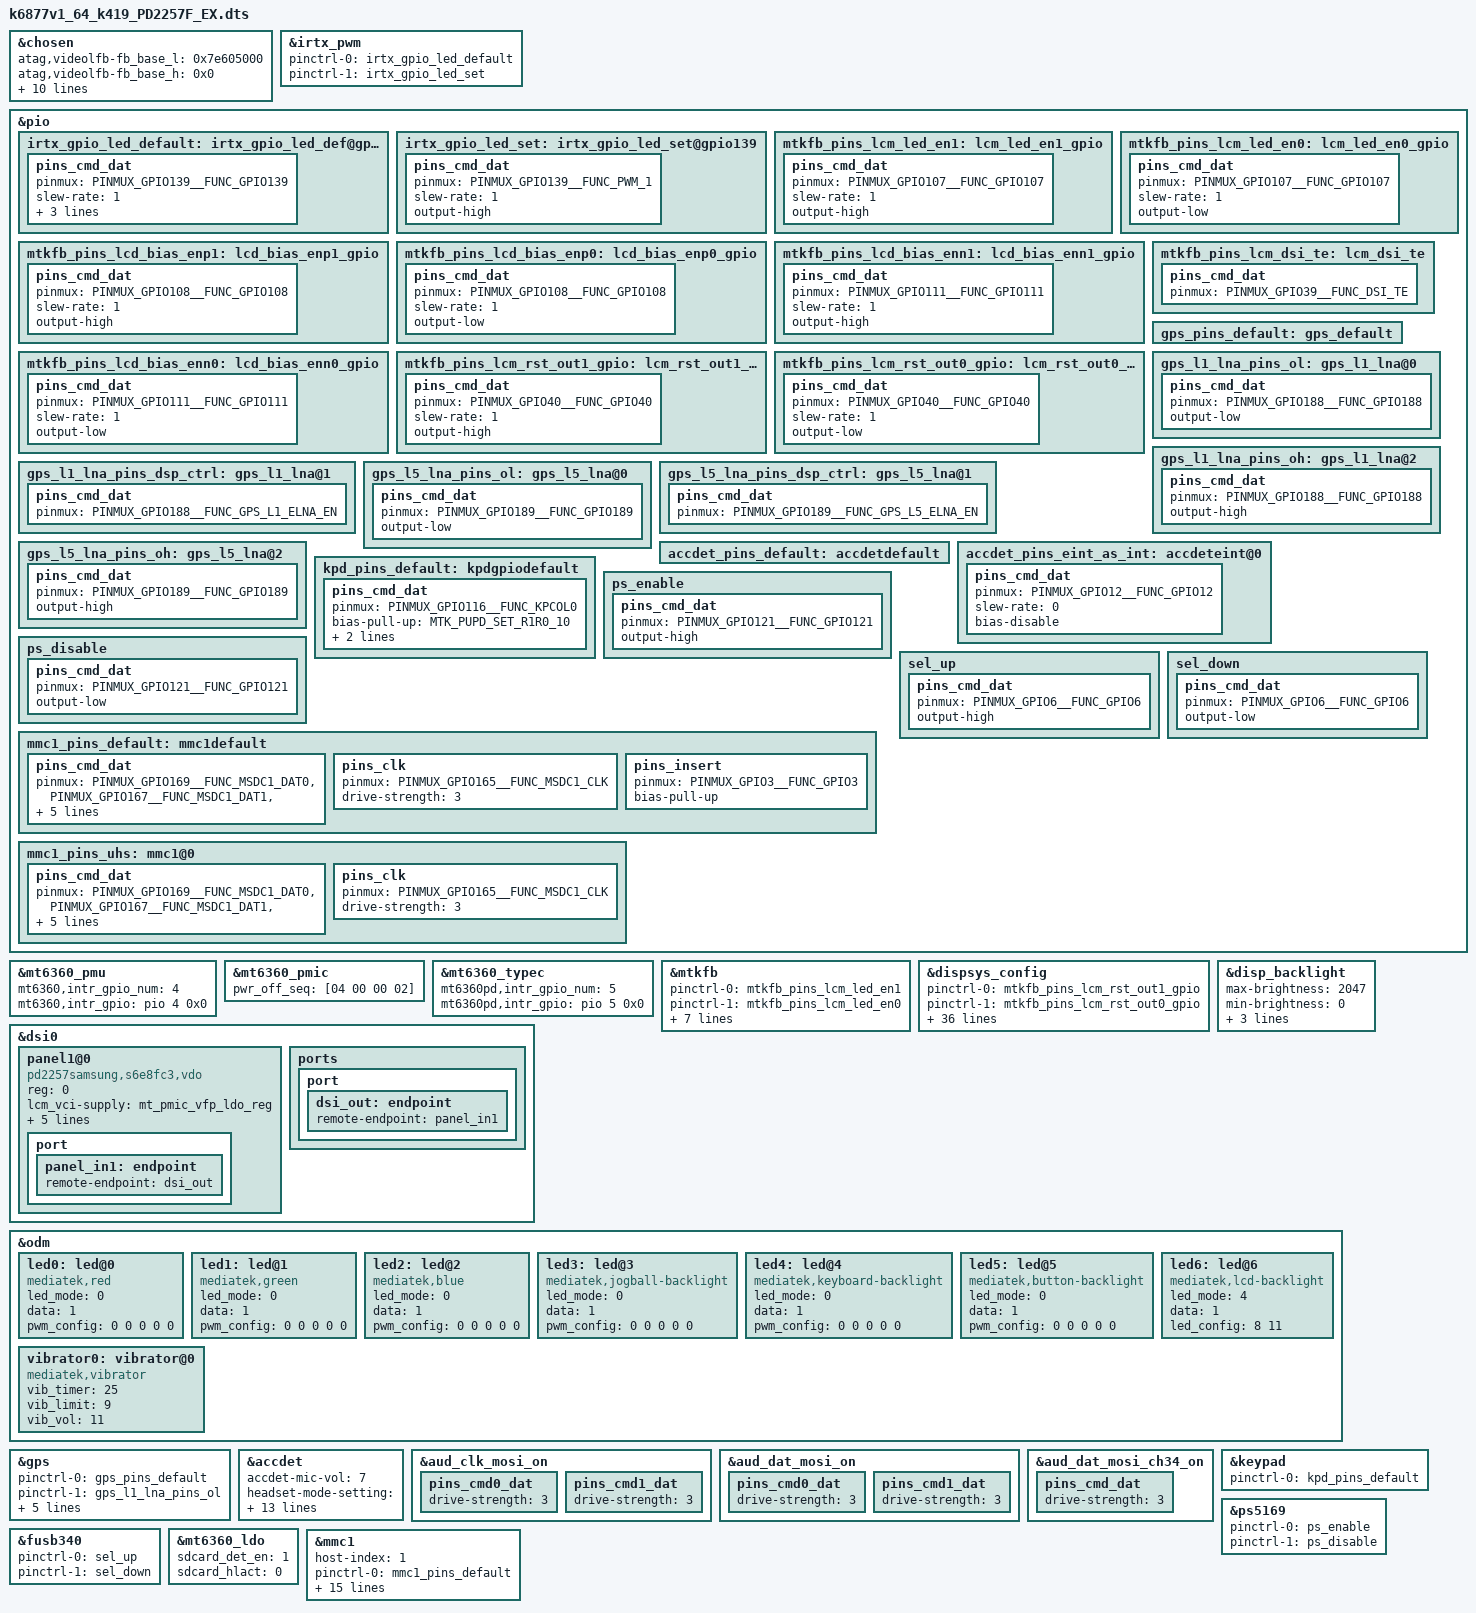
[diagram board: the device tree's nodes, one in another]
// SPDX-License-Identifier: GPL-2.0
/*
 * Copyright (c) 2021 MediaTek Inc.
 */

/dts-v1/;
/plugin/;
#include <generated/autoconf.h>
#include <dt-bindings/interrupt-controller/irq.h>
#include <dt-bindings/interrupt-controller/arm-gic.h>
#include <dt-bindings/pinctrl/mt6877-pinfunc.h>
#include "mtk6877t-vivo-tp-PD2257F_EX.dtsi"
#include "mediatek/fingerprint/mtk6877-vivo-fp-PD2257F_EX.dtsi"
#include <dt-bindings/gpio/gpio.h>
#include <dt-bindings/mmc/mt6877-msdc.h>

/* chosen */
&chosen {
	atag,videolfb-fb_base_l = <0x7e605000>;
	atag,videolfb-fb_base_h = <0x0>;
	atag,videolfb-islcmfound = <1>;
	atag,videolfb-islcm_inited = <0>;
	atag,videolfb-fps= <6000>;
	atag,videolfb-vramSize= <0x1be0000>;
	default-backlight-level = <573>;
	atag,videolfb-project-name= "pd2257";
	atag,vivo-dsi-panel-type = "oled";
	atag,hbm-event-support;
	atag,videolfb-lcmname=
		"td4330_fhdp_dsi_cmd_auo_rt4831_drv";
};

/* IRTX GPIO Start */
&irtx_pwm {
	pinctrl-names = "irtx_gpio_led_default", "irtx_gpio_led_set";
	pinctrl-0 = <&irtx_gpio_led_default>;
	pinctrl-1 = <&irtx_gpio_led_set>;
	status = "okay";
};

&pio {
       /* IRTX GPIO Settings -Start */
       /* default: GPIO0, output, high */
       irtx_gpio_led_default:irtx_gpio_led_def@gpio139 {
               pins_cmd_dat {
                       pinmux = <PINMUX_GPIO139__FUNC_GPIO139>;
                       slew-rate = <1>;
                       bias-disable;
                       output-low;
                       input-schmitt-enable = <0>;
               };
       };

       irtx_gpio_led_set:irtx_gpio_led_set@gpio139 {
               pins_cmd_dat {
                       pinmux = <PINMUX_GPIO139__FUNC_PWM_1>;
                       slew-rate = <1>;
                       output-high;
               };
       };
};

/* IRTX GPIO Settings -End */

&mt6360_pmu {
	mt6360,intr_gpio_num = <4>; /* direct defined GPIO num */
	mt6360,intr_gpio = <&pio 4 0x0>;
};

&mt6360_pmic {
	pwr_off_seq = [04 00 00 02];
};

&mt6360_typec {
	mt6360pd,intr_gpio_num = <5>; /* direct defined GPIO num */
	mt6360pd,intr_gpio = <&pio 5 0x0>;
};

&pio {
	mtkfb_pins_lcm_led_en1: lcm_led_en1_gpio {
		pins_cmd_dat {
			pinmux = <PINMUX_GPIO107__FUNC_GPIO107>;
			slew-rate = <1>;
			output-high;
		};
	};

	mtkfb_pins_lcm_led_en0: lcm_led_en0_gpio {
		pins_cmd_dat {
			pinmux = <PINMUX_GPIO107__FUNC_GPIO107>;
			slew-rate = <1>;
			output-low;
		};
	};

	mtkfb_pins_lcd_bias_enp1: lcd_bias_enp1_gpio {
		pins_cmd_dat {
			pinmux = <PINMUX_GPIO108__FUNC_GPIO108>;
			slew-rate = <1>;
			output-high;
		};
	};

	mtkfb_pins_lcd_bias_enp0: lcd_bias_enp0_gpio {
		pins_cmd_dat {
			pinmux = <PINMUX_GPIO108__FUNC_GPIO108>;
			slew-rate = <1>;
			output-low;
		};
	};

	mtkfb_pins_lcd_bias_enn1: lcd_bias_enn1_gpio {
		pins_cmd_dat {
			pinmux = <PINMUX_GPIO111__FUNC_GPIO111>;
			slew-rate = <1>;
			output-high;
		};
	};

	mtkfb_pins_lcd_bias_enn0: lcd_bias_enn0_gpio {
		pins_cmd_dat {
			pinmux = <PINMUX_GPIO111__FUNC_GPIO111>;
			slew-rate = <1>;
			output-low;
		};
	};

	mtkfb_pins_lcm_rst_out1_gpio: lcm_rst_out1_gpio {
		pins_cmd_dat {
			pinmux = <PINMUX_GPIO40__FUNC_GPIO40>;
			slew-rate = <1>;
			output-high;
		};
	};

	mtkfb_pins_lcm_rst_out0_gpio: lcm_rst_out0_gpio {
		pins_cmd_dat {
			pinmux = <PINMUX_GPIO40__FUNC_GPIO40>;
			slew-rate = <1>;
			output-low;
		};
	};
	mtkfb_pins_lcm_dsi_te: lcm_dsi_te {
		pins_cmd_dat {
			pinmux = <PINMUX_GPIO39__FUNC_DSI_TE>;
		};
	};
};

&mtkfb {
	pinctrl-names = "lcm_led_en1_gpio", "lcm_led_en0_gpio",
		"lcd_bias_enp1_gpio", "lcd_bias_enp0_gpio",
		"lcd_bias_enn1_gpio", "lcd_bias_enn0_gpio",
		"lcm_rst_out1_gpio", "lcm_rst_out0_gpio",
		"mode_te_te";
	pinctrl-0 = <&mtkfb_pins_lcm_led_en1>;
	pinctrl-1 = <&mtkfb_pins_lcm_led_en0>;
	pinctrl-2 = <&mtkfb_pins_lcd_bias_enp1>;
	pinctrl-3 = <&mtkfb_pins_lcd_bias_enp0>;
	pinctrl-4 = <&mtkfb_pins_lcd_bias_enn1>;
	pinctrl-5 = <&mtkfb_pins_lcd_bias_enn0>;
	pinctrl-6 = <&mtkfb_pins_lcm_rst_out1_gpio>;
	pinctrl-7 = <&mtkfb_pins_lcm_rst_out0_gpio>;
	pinctrl-8 = <&mtkfb_pins_lcm_dsi_te>;
	status = "okay";
};
&dispsys_config {
	pinctrl-names =
		"lcm_rst_out1_gpio", "lcm_rst_out0_gpio",
		"mode_te_te";
	pinctrl-0 = <&mtkfb_pins_lcm_rst_out1_gpio>;
	pinctrl-1 = <&mtkfb_pins_lcm_rst_out0_gpio>;
	pinctrl-2 = <&mtkfb_pins_lcm_dsi_te>;
	status = "okay";
	helper-name = "MTK_DRM_OPT_STAGE",
	"MTK_DRM_OPT_USE_CMDQ",
	"MTK_DRM_OPT_USE_M4U",
	"MTK_DRM_OPT_SODI_SUPPORT",
	"MTK_DRM_OPT_IDLE_MGR",
	"MTK_DRM_OPT_IDLEMGR_SWTCH_DECOUPLE",
	"MTK_DRM_OPT_IDLEMGR_BY_REPAINT",
	"MTK_DRM_OPT_IDLEMGR_ENTER_ULPS",
	"MTK_DRM_OPT_IDLEMGR_KEEP_LP11",
	"MTK_DRM_OPT_DYNAMIC_RDMA_GOLDEN_SETTING",
	"MTK_DRM_OPT_IDLEMGR_DISABLE_ROUTINE_IRQ",
	"MTK_DRM_OPT_MET_LOG",
	"MTK_DRM_OPT_USE_PQ",
	"MTK_DRM_OPT_ESD_CHECK_RECOVERY",
	"MTK_DRM_OPT_ESD_CHECK_SWITCH",
	"MTK_DRM_OPT_PRESENT_FENCE",
	"MTK_DRM_OPT_RDMA_UNDERFLOW_AEE",
	"MTK_DRM_OPT_DSI_UNDERRUN_AEE",
	"MTK_DRM_OPT_HRT",
	"MTK_DRM_OPT_HRT_MODE",
	"MTK_DRM_OPT_DELAYED_TRIGGER",
	"MTK_DRM_OPT_OVL_EXT_LAYER",
	"MTK_DRM_OPT_AOD",
	"MTK_DRM_OPT_RPO",
	"MTK_DRM_OPT_DUAL_PIPE",
	"MTK_DRM_OPT_DC_BY_HRT",
	"MTK_DRM_OPT_OVL_WCG",
	"MTK_DRM_OPT_OVL_SBCH",
	"MTK_DRM_OPT_COMMIT_NO_WAIT_VBLANK",
	"MTK_DRM_OPT_MET",
	"MTK_DRM_OPT_REG_PARSER_RAW_DUMP",
	"MTK_DRM_OPT_VP_PQ",
	"MTK_DRM_OPT_GAME_PQ",
	"MTK_DRM_OPT_MMPATH",
	"MTK_DRM_OPT_HBM",
	"MTK_DRM_OPT_VDS_PATH_SWITCH",
	"MTK_DRM_OPT_LAYER_REC",
	"MTK_DRM_OPT_CLEAR_LAYER",
	"MTK_DRM_OPT_LFR",
	"MTK_DRM_OPT_DYN_MIPI_CHANGE",
	"MTK_DRM_OPT_SF_PF";

	helper-value = <0>, /*MTK_DRM_OPT_STAGE*/
		<1>, /*MTK_DRM_OPT_USE_CMDQ*/
		<1>, /*MTK_DRM_OPT_USE_M4U*/
		<0>, /*MTK_DRM_OPT_SODI_SUPPORT*/
		<1>, /*MTK_DRM_OPT_IDLE_MGR*/
		<0>, /*MTK_DRM_OPT_IDLEMGR_SWTCH_DECOUPLE*/
		<1>, /*MTK_DRM_OPT_IDLEMGR_BY_REPAINT*/
		<0>, /*MTK_DRM_OPT_IDLEMGR_ENTER_ULPS*/
		<0>, /*MTK_DRM_OPT_IDLEMGR_KEEP_LP11*/
		<0>, /*MTK_DRM_OPT_DYNAMIC_RDMA_GOLDEN_SETTING*/
		<1>, /*MTK_DRM_OPT_IDLEMGR_DISABLE_ROUTINE_IRQ*/
		<0>, /*MTK_DRM_OPT_MET_LOG*/
		<1>, /*MTK_DRM_OPT_USE_PQ*/
		<1>, /*MTK_DRM_OPT_ESD_CHECK_RECOVERY*/
		<1>, /*MTK_DRM_OPT_ESD_CHECK_SWITCH*/
		<1>, /*MTK_DRM_OPT_PRESENT_FENCE*/
		<1>, /*MTK_DRM_OPT_RDMA_UNDERFLOW_AEE*/
		<1>, /*MTK_DRM_OPT_DSI_UNDERRUN_AEE*/
		<1>, /*MTK_DRM_OPT_HRT*/
		<1>, /*MTK_DRM_OPT_HRT_MODE*/
		<0>, /*MTK_DRM_OPT_DELAYED_TRIGGER*/
		<1>, /*MTK_DRM_OPT_OVL_EXT_LAYER*/
		<1>, /*MTK_DRM_OPT_AOD*/
		<1>, /*MTK_DRM_OPT_RPO*/
		<0>, /*MTK_DRM_OPT_DUAL_PIPE*/
		<0>, /*MTK_DRM_OPT_DC_BY_HRT*/
		<0>, /*MTK_DRM_OPT_OVL_WCG*/
		<0>, /*MTK_DRM_OPT_OVL_SBCH*/
		<1>, /*MTK_DRM_OPT_COMMIT_NO_WAIT_VBLANK*/
		<0>, /*MTK_DRM_OPT_MET*/
		<0>, /*MTK_DRM_OPT_REG_PARSER_RAW_DUMP*/
		<0>, /*MTK_DRM_OPT_VP_PQ*/
		<0>, /*MTK_DRM_OPT_GAME_PQ*/
		<0>, /*MTK_DRM_OPT_MMPATH*/
		<1>, /*MTK_DRM_OPT_HBM*/
		<0>, /*MTK_DRM_OPT_VDS_PATH_SWITCH*/
		<0>, /*MTK_DRM_OPT_LAYER_REC*/
		<1>, /*MTK_DRM_OPT_CLEAR_LAYER*/
		<0>, /*MTK_DRM_OPT_LFR*/
		<1>, /*MTK_DRM_OPT_DYN_MIPI_CHANGE*/
		<0>; /*MTK_DRM_OPT_SF_PF*/
};
&disp_backlight {
	max-brightness = <2047>;
	min-brightness = <0>;
	led-bits = <11>;
	default-brightness = <573>;
	default-state = "on";
};

&dsi0 {
	status = "okay";
	#address-cells = <1>;
	#size-cells = <0>;
	panel1@0 {
		compatible = "pd2257samsung,s6e8fc3,vdo";
		reg = <0>;
		lcm_vci-supply = <&mt_pmic_vfp_ldo_reg>; //LDO1
		vddi_en-gpios = <&pio 16 0>;
		vddr_en-gpios = <&pio 139 0>;
		err_flag-gpios = <&pio 9 0>;
		elvdd_ctrl-gpios = <&pio 138 0>;
		reset-gpios = <&pio 40 0>;
		pinctrl-names = "default";
		port {
			panel_in1: endpoint {
				remote-endpoint = <&dsi_out>;
			};
		};
	};
	ports {
		port {
			dsi_out: endpoint {
				remote-endpoint = <&panel_in1>;
			};
		};
	};
};

&odm {
	led0:led@0 {
		compatible = "mediatek,red";
		led_mode = <0>;
		data = <1>;
		pwm_config = <0 0 0 0 0>;
	};
	led1:led@1 {
		compatible = "mediatek,green";
		led_mode = <0>;
		data = <1>;
		pwm_config = <0 0 0 0 0>;
	};
	led2:led@2 {
		compatible = "mediatek,blue";
		led_mode = <0>;
		data = <1>;
		pwm_config = <0 0 0 0 0>;
	};
	led3:led@3 {
		compatible = "mediatek,jogball-backlight";
		led_mode = <0>;
		data = <1>;
		pwm_config = <0 0 0 0 0>;
	};
	led4:led@4 {
		compatible = "mediatek,keyboard-backlight";
		led_mode = <0>;
		data = <1>;
		pwm_config = <0 0 0 0 0>;
	};
	led5:led@5 {
		compatible = "mediatek,button-backlight";
		led_mode = <0>;
		data = <1>;
		pwm_config = <0 0 0 0 0>;
	};
	led6:led@6 {
		compatible = "mediatek,lcd-backlight";
		led_mode = <4>; /*5:cpu pwm 4:lcm pwm*/
		data = <1>;
		led_config = <8 11>;
	};
	vibrator0:vibrator@0 {
		compatible = "mediatek,vibrator";
		vib_timer = <25>;
		vib_limit = <9>;
		vib_vol= <11>;
	};
};

/* GPS GPIO standardization start */
&pio {
	gps_pins_default: gps_default {
	};
	gps_l1_lna_pins_ol: gps_l1_lna@0 {
		pins_cmd_dat {
			pinmux = <PINMUX_GPIO188__FUNC_GPIO188>;
			output-low;
		};
	};
	gps_l1_lna_pins_dsp_ctrl: gps_l1_lna@1 {
		pins_cmd_dat {
			pinmux = <PINMUX_GPIO188__FUNC_GPS_L1_ELNA_EN>;
		};
	};
	gps_l1_lna_pins_oh: gps_l1_lna@2 {
		pins_cmd_dat {
			pinmux = <PINMUX_GPIO188__FUNC_GPIO188>;
			output-high;
		};
	};
	gps_l5_lna_pins_ol: gps_l5_lna@0 {
		pins_cmd_dat {
			pinmux = <PINMUX_GPIO189__FUNC_GPIO189>;
			output-low;
		};
	};
	gps_l5_lna_pins_dsp_ctrl: gps_l5_lna@1 {
		pins_cmd_dat {
			pinmux = <PINMUX_GPIO189__FUNC_GPS_L5_ELNA_EN>;
		};
	};
	gps_l5_lna_pins_oh: gps_l5_lna@2 {
		pins_cmd_dat {
			pinmux = <PINMUX_GPIO189__FUNC_GPIO189>;
			output-high;
		};
	};
};
&gps {
	pinctrl-names = "default",
		"gps_l1_lna_disable",
		"gps_l1_lna_dsp_ctrl",
		"gps_l1_lna_enable",
		"gps_l5_lna_disable",
		"gps_l5_lna_dsp_ctrl",
		"gps_l5_lna_enable";
	pinctrl-0 = <&gps_pins_default>;
	pinctrl-1 = <&gps_l1_lna_pins_ol>;
	pinctrl-2 = <&gps_l1_lna_pins_dsp_ctrl>;
	pinctrl-3 = <&gps_l1_lna_pins_oh>;
	pinctrl-4 = <&gps_l5_lna_pins_ol>;
	pinctrl-5 = <&gps_l5_lna_pins_dsp_ctrl>;
	pinctrl-6 = <&gps_l5_lna_pins_oh>;
	status = "okay";
};
/* GPS GPIO standardization end */

&accdet {
	/* accdet micbias voltage: 0x09:2.85v 0x08:2.8v 0x07,
	 * 2.7v;0x05,2.5v;0x02,1.9v
	 */
	accdet-mic-vol = <7>;
	/* accdet pwm_width, pwm_thresh, fall_delay, rise_delay
	 * debounce0, debounce1, debounce3, debounce4
	 * eint pwm_width, eint pwm_thresh
	 * eint deb(debounce0, debounce1, debounce2, debounce3), inv_debounce
	 */
	headset-mode-setting = <0x500 0x500 1 0x1f0
				0x800 0x800 0x2000 0x44
				0x4 0x1
				0x5 0x3 0x3 0x5 0xe>;
	accdet-plugout-debounce = <16>;
	/*1:ACC mode, 2:low cost without in bias, 6:low cost with in bias*/
	accdet-mic-mode = <2>;
	/*0--MD_MAX--UP_MAX--DW_MAX*/
	headset-three-key-threshold = <0 90 210 430>;
	headset-three-key-threshold-CDD = <0 121 192 600>;
	/*0--MD_MAX--VOICE_MAX--UP_MAX--DW_MAX*/
	headset-four-key-threshold = <0 60 106 210 430>;

	/* select VTH to 2v and 500k, use internal resitance */
	eint_use_ext_res = <0>;
	pinctrl-names = "default", "state_eint_as_int";
	pinctrl-0 = <&accdet_pins_default>;
	pinctrl-1 = <&accdet_pins_eint_as_int>;
	interrupt-parent = <&pio>;
	interrupts = <12 IRQ_TYPE_LEVEL_LOW>;
	deb-gpios = <&pio 12 0>;
	debounce = <256000>;
	status = "okay";
};

/* Audio add for modify mosi driving start */
/* 0:2mA 1:4mA 2:6mA 3:8mA 4:10mA 5:12mA 6:14mA 7:16mA */
&aud_clk_mosi_on {
	pins_cmd0_dat {
		drive-strength = <3>;
	};
	pins_cmd1_dat {
		drive-strength = <3>;
	};
};
&aud_dat_mosi_on {
	pins_cmd0_dat {
		drive-strength = <3>;
	};
	pins_cmd1_dat {
		drive-strength = <3>;
	};
};
&aud_dat_mosi_ch34_on {
	pins_cmd_dat {
		drive-strength = <3>;
	};
};
/* Audio add for modify mosi driving end */

&pio {
	accdet_pins_default: accdetdefault {
	};
	accdet_pins_eint_as_int: accdeteint@0 {
		pins_cmd_dat {
			pinmux = <PINMUX_GPIO12__FUNC_GPIO12>;
			slew-rate = <0>;
			bias-disable;
		};
	};
};

/* keypad start */
&keypad {
	pinctrl-names = "default";
	pinctrl-0 = <&kpd_pins_default>;
};

&pio {
	kpd_pins_default: kpdgpiodefault {
		pins_cmd_dat {
			pinmux = <PINMUX_GPIO116__FUNC_KPCOL0>;
			bias-pull-up = <MTK_PUPD_SET_R1R0_10>;
			input-enable;
			input-schmitt-enable;
		};
	};
};
/* keypad end */

&ps5169{
	pinctrl-names = "enable", "disable";
	pinctrl-0 = <&ps_enable>;
	pinctrl-1 = <&ps_disable>;
	status = "okay";
};

&fusb340 {
	pinctrl-names = "sel_up", "sel_down";
	pinctrl-0 = <&sel_up>;
	pinctrl-1 = <&sel_down>;
	status = "okay";
};

&pio {
	ps_enable: ps_enable {
		pins_cmd_dat {
			pinmux = <PINMUX_GPIO121__FUNC_GPIO121>;
			output-high;
		};
	};

	ps_disable: ps_disable {
		pins_cmd_dat {
			pinmux = <PINMUX_GPIO121__FUNC_GPIO121>;
			output-low;
		};
	};

	sel_up: sel_up {
		pins_cmd_dat {
			pinmux = <PINMUX_GPIO6__FUNC_GPIO6>;
			output-high;
		};
	};

	sel_down: sel_down {
		pins_cmd_dat {
			pinmux = <PINMUX_GPIO6__FUNC_GPIO6>;
			output-low;
		};
	};
};

/*#include <k6877v1_64_k419/cust.dtsi> */
#include "mediatek/cust_vivo_PD2257F_EX.dtsi"
#include "mediatek/cust_mt6877_touch_1080x2300.dtsi"
#include "mediatek/cust_mt6877_camera.dtsi"
/*End of this file, DO NOT ADD ANYTHING HERE*/

/*add TF begin*/

&mt6360_ldo {
	sdcard_det_en = <1>;
	sdcard_hlact = <0>;
};

&mmc1 {
	status = "okay";
	host-index = <1>;
	pinctrl-names = "default", "state_uhs";
	pinctrl-0 = <&mmc1_pins_default>;
	pinctrl-1 = <&mmc1_pins_uhs>;
	bus-width = <4>;
	max-frequency = <50000000>;
	cap-sd-highspeed;
	sd-uhs-sdr12;
	sd-uhs-sdr25;
	sd-uhs-sdr50;
/*	sd-uhs-sdr104;	*/
	sd-uhs-ddr50;
	cd-gpios = <&pio 3 GPIO_ACTIVE_HIGH>;
	vmmc-supply = <&mt_pmic_vmch_ldo_reg>;
	vqmmc-supply = <&mt_pmic_vmc_ldo_reg>;
	no-mmc;
	no-sdio;
	fast_power_off;
	host-function = <MSDC_SD>;
};


&pio {
	mmc1_pins_default: mmc1default {
		pins_cmd_dat {
			pinmux = <PINMUX_GPIO169__FUNC_MSDC1_DAT0>,
				<PINMUX_GPIO167__FUNC_MSDC1_DAT1>,
				<PINMUX_GPIO168__FUNC_MSDC1_DAT2>,
				<PINMUX_GPIO166__FUNC_MSDC1_DAT3>,
				<PINMUX_GPIO164__FUNC_MSDC1_CMD>;
			input-enable;
			drive-strength = <3>;
		};

		pins_clk {
			pinmux = <PINMUX_GPIO165__FUNC_MSDC1_CLK>;
			drive-strength = <3>;
		};

		pins_insert {
			pinmux = <PINMUX_GPIO3__FUNC_GPIO3>;
			bias-pull-up;
		};
	};

	mmc1_pins_uhs: mmc1@0{
		pins_cmd_dat {
			pinmux = <PINMUX_GPIO169__FUNC_MSDC1_DAT0>,
				<PINMUX_GPIO167__FUNC_MSDC1_DAT1>,
				<PINMUX_GPIO168__FUNC_MSDC1_DAT2>,
				<PINMUX_GPIO166__FUNC_MSDC1_DAT3>,
				<PINMUX_GPIO164__FUNC_MSDC1_CMD>;
			input-enable;
			drive-strength = <3>;
		};

		pins_clk {
			pinmux = <PINMUX_GPIO165__FUNC_MSDC1_CLK>;
			drive-strength = <3>;
		};
	};
};

/*add TF end*/
